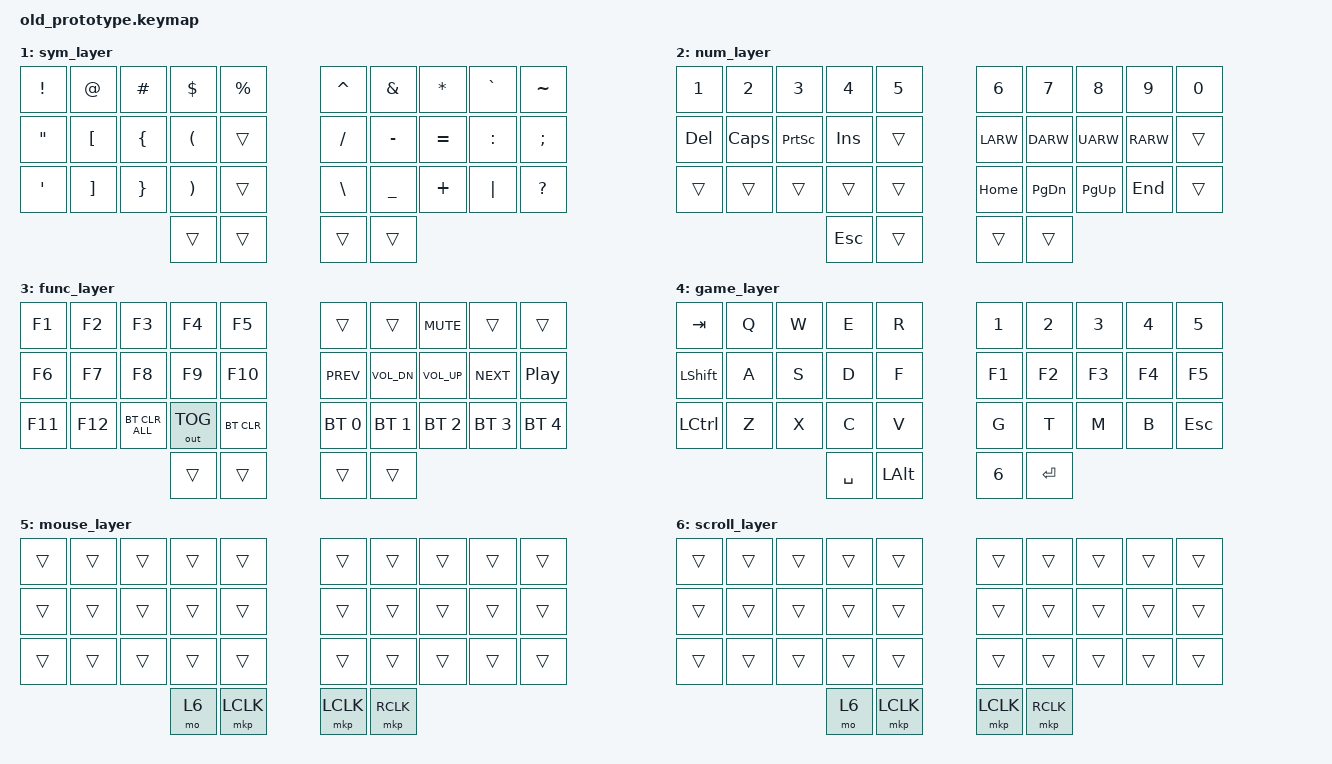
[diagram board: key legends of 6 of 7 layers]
// Copyright (c) 2022 The ZMK Contributors
// SPDX-License-Identifier: MIT

/*
 * ============================================================================
 * ACTIVE KEYMAP - This is the keymap actually used by the left/right halves
 * ============================================================================
 * This file overrides the shield default (config/boards/shields/old_prototype/old_prototype.keymap)
 * Edit THIS file to change your keyboard layout.
 *
 * Note: The dongle uses a separate keymap (config/boards/shields/old_prototype/old_prototype_dongle.keymap)
 * which must have matching layer definitions for mouse/scroll functionality.
 */

#include <behaviors.dtsi>
#include <dt-bindings/zmk/keys.h>
#include <dt-bindings/zmk/mouse.h>
#include <dt-bindings/zmk/bt.h>
#include <dt-bindings/zmk/outputs.h>

// Home row mods macro
#define HRML(k2,k3,k4) &ht LALT k2  &ht LCTRL k3  &ht LGUI k4
#define HRMR(k1,k2,k3) &ht RGUI k1  &ht RCTRL k2  &ht RALT k3
#define WHRML(k2,k3,k4) &ht LALT k2  &ht LGUI k3  &ht LCTRL k4
#define WHRMR(k1,k2,k3) &ht RCTRL k1  &ht RGUI k2  &ht RALT k3

#define SYM 1
#define NUM 2
#define FUNC 3
#define GAME 4
#define MOUSE_TP 5

&mt {
    flavor = "tap-preferred";
    tapping_term_ms = <200>;
};

&mmv {
   time-to-max-speed-ms = <680>;
   acceleration-exponent=<2>;
};

/ {
    behaviors {
        ht: hold_tap {
            label = "hold_tap";
            compatible = "zmk,behavior-hold-tap";
            #binding-cells = <2>;
            flavor = "tap-preferred";
            tapping-term-ms = <220>;
            quick-tap-ms = <150>;
            global-quick-tap;
            bindings = <&kp>, <&kp>;
        };
        hm: homerow_mods {
            compatible = "zmk,behavior-hold-tap";
            label = "HOMEROW_MODS";
            #binding-cells = <2>;
            tapping-term-ms = <200>;
            quick_tap_ms = <0>;
            flavor = "tap-preferred";
            bindings = <&kp>, <&kp>;
        };
        td: tapdance {
            compatible = "zmk,behavior-hold-tap";
            label = "TAPDANCE";
            #binding-cells = <2>;
            tapping-term-ms = <150>;
            quick_tap_ms = <0>;
            flavor = "tap-preferred";
            bindings = <&kp>, <&kp>;
        };
        tog_game_hold: tog_game_hold {
            compatible = "zmk,behavior-hold-tap";
            #binding-cells = <2>;
            flavor = "hold-preferred";
            tapping-term-ms = <2000>;
            bindings = <&tog>, <&none>;
        };
    };

    combos {
        compatible = "zmk,combos";
        combo_game_toggle {
            timeout-ms = <50>;
            // Don't fire mid-typing: only when both keys are pressed after a
            // typing pause, so a fast "o p" roll can't toggle the game layer.
            require-prior-idle-ms = <150>;
            key-positions = <8 9>;  // O + P positions
            bindings = <&tog_game_hold GAME 0>;
            layers = <0 GAME>;  // Active on base and game layers
        };
    };

    conditional_layers {
        compatible = "zmk,conditional-layers";
        func_layer {
            if-layers = <NUM SYM>;
            then-layer = <FUNC>;
        };
    };

   keymap {
        compatible = "zmk,keymap";
        default_layer {
            bindings = <
        //╭──────────┬──────────┬──────────┬──────────┬──────────╮   ╭──────────┬──────────┬──────────┬──────────┬──────────╮
        //│  Q       │  W       │  E       │  R       │  T       │   │  Y       │  U       │  I       │  O       │  P       │
            &kp Q      &kp W      &kp E      &kp R      &kp T          &kp Y      &kp U      &kp I      &kp O      &kp P
        //├──────────┼──────────┼──────────┼──────────┼──────────┤   ├──────────┼──────────┼──────────┼──────────┼──────────┤
        //│  A       │  S       │  D       │  F       │  G       │   │  H       │  J       │  K       │  L       │BACKSPACE │
            &kp A    WHRML(S,         D,         F)     &kp G          &kp H      WHRMR(J,        K,           L)   &kp BSPC
        //├──────────┼──────────┼──────────┼──────────┼──────────┤   ├──────────┼──────────┼──────────┼──────────┼──────────┤
        //│  Z       │  X       │  C       │  V       │  B       │   │  N       │  M       │ , <      │ . >      │ DELETE   │
            &kp Z      &kp X      &kp C      &kp V      &kp B          &kp N      &kp M      &kp COMMA  &kp DOT    &kp DEL
        //╰──────────┴──────────┴──────────┼──────────┼──────────┤   ├──────────┼──────────┼──────────┴──────────┴──────────╯
                                           &kp SPACE  &lt SYM TAB    &lt NUM ENTER  &kp LSHIFT
        //                                 ╰──────────┴──────────╯   ╰──────────┴──────────╯
            >;
        };

        sym_layer {
            bindings = <
        //╭──────────┬──────────┬──────────┬──────────┬──────────╮   ╭──────────┬──────────┬──────────┬──────────┬──────────╮
        //│  !       │  @       │  #       │  $       │  %       │   │  ^       │  &       │  *       │  `       │  ~       │
            &kp EXCL   &kp AT     &kp HASH   &kp DLLR   &kp PRCNT      &kp CARET  &kp AMPS   &kp ASTRK  &kp GRAVE   &kp TILDE
        //├──────────┼──────────┼──────────┼──────────┼──────────┤   ├──────────┼──────────┼──────────┼──────────┼──────────┤
        //│  "       │  [       │  {       │  (       │          │   │   /      │  -       │  =       │     :    │  ;       │
            &kp DQT  &kp LBKT   &kp LBRC   &kp LPAR   &trans         &kp FSLH   &kp MINUS  &kp EQUAL  &kp COLON   &kp SEMI
        //├──────────┼──────────┼──────────┼──────────┼──────────┤   ├──────────┼──────────┼──────────┼──────────┼──────────┤
        //│  '       │  ]       │  }       │  )       │          │   │    \     │  _       │  +       │  │       │   ?      │
            &kp SQT     &kp RBKT   &kp RBRC   &kp RPAR   &trans         &kp BSLH   &kp UNDER  &kp PLUS   &kp PIPE  &kp QMARK
        //╰──────────┴──────────┴──────────┼──────────┼──────────┤   ├──────────┼──────────┼──────────┴──────────┴──────────╯
                                             &trans     &trans         &trans     &trans
        //                                 ╰──────────┴──────────╯   ╰──────────┴──────────╯
            >;
        };

        num_layer {
            bindings = <
        //╭──────────┬──────────┬──────────┬──────────┬──────────╮   ╭──────────┬──────────┬──────────┬──────────┬──────────╮
        //│ 1        │  2       │  3       │  4       │  5       │   │ 6        │ 7        │ 8        │ 9        │   0      │
            &kp N1    &kp N2     &kp N3     &kp N4     &kp N5          &kp N6     &kp N7     &kp N8     &kp N9      &kp N0
        //├──────────┼──────────┼──────────┼──────────┼──────────┤   ├──────────┼──────────┼──────────┼──────────┼──────────┤
        //│ DELETE   │ CapsLock │ PrintSc  │  INSERT  │          |   |          │ LEFT     │ DOWN     │ UP       │ RIGHT    │
            &kp DEL   &kp CAPS   &kp PSCRN  &kp INS     &trans           &kp LARW   &kp DARW   &kp UARW   &kp RARW   &trans 
        //├──────────┼──────────┼──────────┼──────────┼──────────┤   ├──────────┼──────────┼──────────┼──────────┼──────────┤
        //│          │          │          │          │          │   │          │ HOME     │ PAGE DN  │ PAGE UP  │ END      │
            &trans    &trans     &trans     &trans      &trans           &kp HOME   &kp PG_DN  &kp PG_UP  &kp END &trans 
        //╰──────────┴──────────┴──────────┼──────────┼──────────┤   ├──────────┼──────────┼──────────┴──────────┴──────────╯
                                             &kp ESC    &trans         &trans     &trans
        //                                 ╰──────────┴──────────╯   ╰──────────┴──────────╯
            >;
        };

        func_layer {
            bindings = <
        //╭──────────┬──────────┬──────────┬──────────┬──────────╮   ╭──────────┬──────────┬──────────┬───────────┬──────────╮
        //│  F1      │  F2      │  F3      │  F4      │  F5      │   │          │          │ VOL MUTE │           │          │
            &kp F1     &kp F2     &kp F3     &kp F4     &kp F5         &trans     &trans     &kp C_MUTE &trans      &trans
        //├──────────┼──────────┼──────────┼──────────┼──────────┤   ├──────────┼──────────┼──────────┼───────────┼──────────┤
        //│  F6      │  F7      │  F8      │  F9      │  F10     │   │ PREVSONG │ VOL DOWN │  VOL UP  │ NEXTSONG  │PAUSEMUSIC│
            &kp F6     &kp F7     &kp F8     &kp F9     &kp F10        &kp C_PREV &kp C_VOL_DN &kp C_VOL_UP &kp C_NEXT &kp C_PP
        //├──────────┼──────────┼──────────┼──────────┼──────────┤   ├──────────┼──────────┼──────────┼───────────┼──────────┤
        //│  F11     │  F12     │ CLR ALL  │ OUT TOG  │ BT CLR   │   │  BT 0    │  BT 1    │  BT 2    |   BT 3    │  BT 4    │
            &kp F11    &kp F12 &bt BT_CLR_ALL &out OUT_TOG &bt BT_CLR   &bt BT_SEL 0 &bt BT_SEL 1 &bt BT_SEL 2 &bt BT_SEL 3 &bt BT_SEL 4
        //╰──────────┴──────────┴──────────┼──────────┼──────────┤   ├──────────┼──────────┼──────────┴───────────┴──────────╯
                                                &trans     &trans         &trans     &trans
        //                                 ╰──────────┴──────────╯   ╰──────────┴──────────╯
            >;
        };


        game_layer {
            bindings = <
        //╭──────────┬──────────┬──────────┬──────────┬──────────╮   ╭──────────┬──────────┬──────────┬──────────┬──────────╮
        //│  TAB     │  Q       │  W       │  E       │  R       │   │  1       │  2       │  3       │  4       │  5       │
            &kp TAB    &kp Q      &kp W      &kp E      &kp R          &kp N1     &kp N2     &kp N3     &kp N4     &kp N5
        //├──────────┼──────────┼──────────┼──────────┼──────────┤   ├──────────┼──────────┼──────────┼──────────┼──────────┤
        //│  LSHIFT  │  A       │  S       │  D       │  F       │   │  F1      │  F2      │  F3      │  F4      │  F5      │
            &kp LSHIFT &kp A      &kp S      &kp D      &kp F          &kp F1     &kp F2     &kp F3     &kp F4     &kp F5
        //├──────────┼──────────┼──────────┼──────────┼──────────┤   ├──────────┼──────────┼──────────┼──────────┼──────────┤
        //│  LCTRL   │  Z       │  X       │  C       │  V       │   │  G       │  T       │  M       │  B       │  ESC     │
            &kp LCTRL  &kp Z      &kp X      &kp C      &kp V          &kp G      &kp T      &kp M      &kp B      &kp ESC
        //╰──────────┴──────────┴──────────┼──────────┼──────────┤   ├──────────┼──────────┼──────────┴──────────┴──────────╯
                                            &kp SPACE  &kp LALT       &kp N6     &kp ENTER
        //                                 ╰──────────┴──────────╯   ╰──────────┴──────────╯
            >;
        };

        mouse_layer {
            bindings = <
        //╭──────────┬──────────┬──────────┬──────────┬──────────╮   ╭──────────┬──────────┬──────────┬──────────┬──────────╮
        //│          │          │          │          │          │   │          │          │          │          │          │
            &trans     &trans     &trans     &trans     &trans         &trans     &trans     &trans     &trans     &trans
        //├──────────┼──────────┼──────────┼──────────┼──────────┤   ├──────────┼──────────┼──────────┼──────────┼──────────┤
        //│          │          │          │          │          │   │          │          │          │          │          │
            &trans     &trans     &trans     &trans     &trans         &trans     &trans     &trans     &trans     &trans
        //├──────────┼──────────┼──────────┼──────────┼──────────┤   ├──────────┼──────────┼──────────┼──────────┼──────────┤
        //│          │          │          │          │          │   │          │          │          │          │          │
            &trans     &trans     &trans     &trans     &trans         &trans     &trans     &trans     &trans     &trans
        //╰──────────┴──────────┴──────────┼──────────┼──────────┤   ├──────────┼──────────┼──────────┴──────────┴──────────╯
        //                                 │  SCROLL  │  LCLICK  │   │  LCLICK  │  RCLICK  │
                                            &mo 6      &mkp LCLK      &mkp LCLK  &mkp RCLK
        //                                 ╰──────────┴──────────╯   ╰──────────┴──────────╯
            >;
        };

        scroll_layer {
            bindings = <
        //╭──────────┬──────────┬──────────┬──────────┬──────────╮   ╭──────────┬──────────┬──────────┬──────────┬──────────╮
        //│          │          │          │          │          │   │          │          │          │          │          │
            &trans     &trans     &trans     &trans     &trans         &trans     &trans     &trans     &trans     &trans
        //├──────────┼──────────┼──────────┼──────────┼──────────┤   ├──────────┼──────────┼──────────┼──────────┼──────────┤
        //│          │          │          │          │          │   │          │          │          │          │          │
            &trans     &trans     &trans     &trans     &trans         &trans     &trans     &trans     &trans     &trans
        //├──────────┼──────────┼──────────┼──────────┼──────────┤   ├──────────┼──────────┼──────────┼──────────┼──────────┤
        //│          │          │          │          │          │   │          │          │          │          │          │
            &trans     &trans     &trans     &trans     &trans         &trans     &trans     &trans     &trans     &trans
        //╰──────────┴──────────┴──────────┼──────────┼──────────┤   ├──────────┼──────────┼──────────┴──────────┴──────────╯
        //                                 │  SCROLL  │  LCLICK  │   │  LCLICK  │  RCLICK  │
                                            &mo 6      &mkp LCLK      &mkp LCLK  &mkp RCLK
        //                                 ╰──────────┴──────────╯   ╰──────────┴──────────╯
            >;
        };
    };
};
